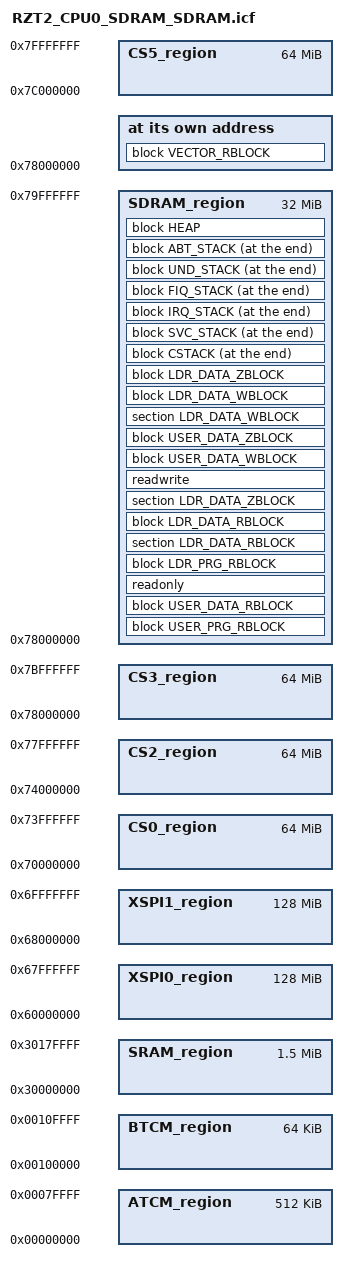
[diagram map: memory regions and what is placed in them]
/*###ICF### Section handled by ICF editor, don't touch! ****/
/*-Editor annotation file-*/
/* IcfEditorFile="$TOOLKIT_DIR$\config\ide\IcfEditor\a_v1_0.xml" */
/*-Specials-*/
define symbol __ICFEDIT_intvec_start__ = 0x78000000;
/*-Memory Regions-*/
define symbol __ICFEDIT_region_ROM_start__ = 0x0;
define symbol __ICFEDIT_region_ROM_end__   = 0x0;
define symbol __ICFEDIT_region_RAM_start__ = 0x0;
define symbol __ICFEDIT_region_RAM_end__   = 0x0;
/*-Sizes-*/

define symbol __ICFEDIT_size_cstack__   = 0x6000;
define symbol __ICFEDIT_size_svcstack__ = 0x1000;
define symbol __ICFEDIT_size_irqstack__ = 0x1000;
define symbol __ICFEDIT_size_fiqstack__ = 0x1000;
define symbol __ICFEDIT_size_undstack__ = 0x1000;
define symbol __ICFEDIT_size_abtstack__ = 0x1000;
define symbol __ICFEDIT_size_heap__     = 0x800000;

/**** End of ICF editor section. ###ICF###*/

define memory mem with size = 4G;

//----------------------------------------------------------------------------
//
// Region definition
//
//----------------------------------------------------------------------------
define region ROM_region   = mem:[from __ICFEDIT_region_ROM_start__   to __ICFEDIT_region_ROM_end__];
define region RAM_region   = mem:[from __ICFEDIT_region_RAM_start__   to __ICFEDIT_region_RAM_end__];

define region ATCM_region   =   mem:[from 0x00000000 size 512K];
define region BTCM_region   =   mem:[from 0x00100000 size  64K];
define region SRAM_region   =   mem:[from 0x30000000 size  1M + 512K];
define region XSPI0_region  =   mem:[from 0x60000000 size 128M];
define region XSPI1_region  =   mem:[from 0x68000000 size 128M];
define region CS0_region    =   mem:[from 0x70000000 size  64M];
define region CS2_region    =   mem:[from 0x74000000 size  64M];
define region CS3_region    =   mem:[from 0x78000000 size  64M];
define region CS5_region    =   mem:[from 0x7C000000 size  64M];

define region SDRAM_region   =   mem:[from 0x78000000 size 32M];  /* 256Mbit SDRAM */

//----------------------------------------------------------------------------
//
// Block definition
//
//----------------------------------------------------------------------------
define block CSTACK    with alignment = 8, size = __ICFEDIT_size_cstack__   { };
define block SVC_STACK with alignment = 8, size = __ICFEDIT_size_svcstack__ { };
define block IRQ_STACK with alignment = 8, size = __ICFEDIT_size_irqstack__ { };
define block FIQ_STACK with alignment = 8, size = __ICFEDIT_size_fiqstack__ { };
define block UND_STACK with alignment = 8, size = __ICFEDIT_size_undstack__ { };
define block ABT_STACK with alignment = 8, size = __ICFEDIT_size_abtstack__ { };
define block HEAP      with alignment = 8, size = __ICFEDIT_size_heap__     { };


define block LDR_PRG_RBLOCK with fixed order
                             { section .text object startup.o,
                               section .text object system.o,
                               section .text object bsp_clocks.o,
                               section .text object bsp_irq.o,
                               section .text object bsp_semaphore.o,
                               section .text object data_init.o,
                               section .text object copy_init3.o }; 

define block LDR_DATA_ZBLOCK { section .bss object startup.o,
                               section .bss object system.o,
                               section .bss object bsp_clocks.o,
                               section .bss object bsp_irq.o,
                               section .bss object bsp_semaphore.o,
                               section .bss object data_init.o,
                               section .bss object copy_init3.o };
define block LDR_DATA_RBLOCK { section .data_init object startup.o,
                               section .data_init object system.o,
                               section .data_init object bsp_clocks.o,
                               section .data_init object bsp_irq.o,
                               section .data_init object bsp_semaphore.o,
                               section .data_init object data_init.o,
                               section .data_init object copy_init3.o };
define block LDR_DATA_WBLOCK { section .data object startup.o,
                               section .data object system.o,
                               section .data object bsp_clocks.o,
                               section .data object bsp_irq.o,
                               section .data object bsp_semaphore.o,
                               section .data object data_init.o,
                               section .data object copy_init3.o };
                               
define block VECTOR_RBLOCK { ro code object vector.o };
define block USER_PRG_RBLOCK { ro code };
define block USER_DATA_ZBLOCK { section .bss };
define block USER_DATA_RBLOCK { section .data_init, section __DLIB_PERTHREAD_init };
define block USER_DATA_WBLOCK { section .data, section __DLIB_PERTHREAD };


//----------------------------------------------------------------------------
//
// Initialization
//
//----------------------------------------------------------------------------
initialize by copy { readwrite }; 
                        
do not initialize  { section .noinit,
                     section .bss object startup.o,
                     section .bss object system.o,
                     section .bss object bsp_clocks.o,
                     section .bss object bsp_irq.o,
                     section .bss object bsp_semaphore.o };
                     
initialize manually  { section .data object startup.o,
                       section .data object system.o,
                       section .data object bsp_clocks.o,
                       section .data object bsp_irq.o,
                       section .data object bsp_semaphore.o };

//----------------------------------------------------------------------------
//
// Placement
//
//----------------------------------------------------------------------------

place in SRAM_region   { };
place in XSPI0_region   { };
place in XSPI1_region   { };
place in CS0_region   { };
place in CS2_region   { };
place in CS3_region   { };
place in CS5_region   { };

//------------------------
// Vector Table
//------------------------
place at address mem: __ICFEDIT_intvec_start__ { block VECTOR_RBLOCK };


//------------------------
// ROM
//------------------------
place in SDRAM_region { block USER_PRG_RBLOCK,
                      block USER_DATA_RBLOCK,
                      readonly };

// for SSBL
place in SDRAM_region  { block LDR_PRG_RBLOCK };
place in SDRAM_region  { section LDR_DATA_RBLOCK, block LDR_DATA_RBLOCK,
                       section LDR_DATA_ZBLOCK }; 

//------------------------
// RAM
//------------------------
place in SDRAM_region   { readwrite };
place in SDRAM_region   { block USER_DATA_WBLOCK,
                        block USER_DATA_ZBLOCK };

// for SSBL
place in SDRAM_region { section LDR_DATA_WBLOCK, block LDR_DATA_WBLOCK,
                       block LDR_DATA_ZBLOCK };


//------------------------
// RAM (Stack)
//------------------------
place at end of SDRAM_region { block CSTACK, block SVC_STACK, block IRQ_STACK,
                              block FIQ_STACK, block UND_STACK, block ABT_STACK };

//------------------------
// RAM (Heap)
//------------------------
place in SDRAM_region { block HEAP };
